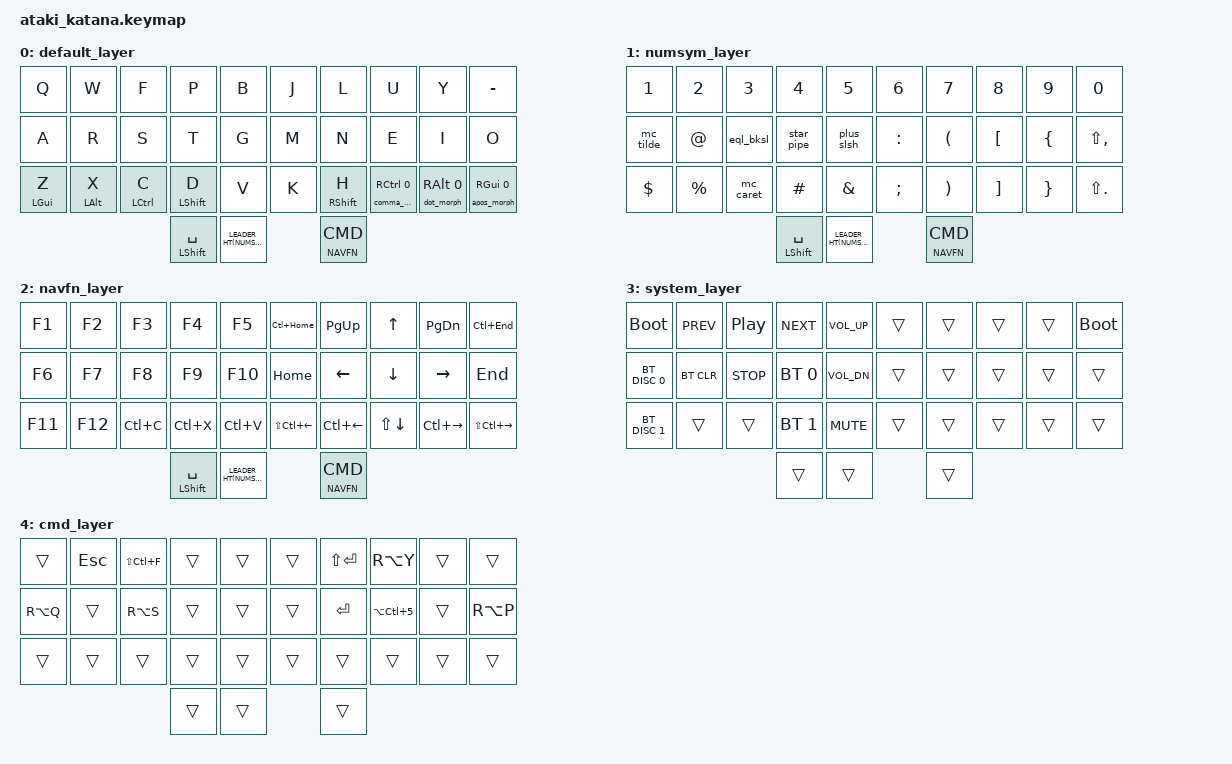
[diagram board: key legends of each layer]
#include <behaviors.dtsi>
#include <dt-bindings/zmk/keys.h>
#include <dt-bindings/zmk/bt.h>
#include <dt-bindings/zmk/pointing.h>
#include "inc/helpers.h"

// Layers
#define BASE 0
#define NUMSYM 1
#define NAVFN 2
#define SYSTEM 3
#define CMD 4
#define BASE_LAYERS BASE

#define ___ &trans

/* How quickly Combo keys must be pressed together */
#define COMBO_TIMEOUT_MS 30
/* Macro timers; can be increased for systems that don't like 0ms Macros */
#define FAST_MACRO_TAP_MS 0
#define FAST_MACRO_WAIT_MS 0

#define LEADER_HT(hold_layer) &leader_ht hold_layer 0

/* Custom base layer punctuation */
SHIFT_MORPH(comma_qust, &kp COMMA, &kp QMARK)
SHIFT_MORPH(dot_exc, &kp DOT, &kp EXCL)
SHIFT_MORPH(eql_bksl, &kp EQUAL, &kp BSLH)
SHIFT_MORPH(star_pipe, &kp STAR, &kp PIPE)
SHIFT_MORPH(plus_slsh, &kp PLUS, &kp FSLH)

MY_HOLD_TAP(dot_morph, &dot_exc, &kp)
MY_HOLD_TAP(comma_morph, &comma_qust, &kp)
MY_HOLD_TAP(apos_morph, &mc_apos, &kp)

#include "inc/urob_leader.h"

/ {
    behaviors {
       ht: hold_tap {
            compatible = "zmk,behavior-hold-tap";
            #binding-cells = <2>;
            flavor = "balanced";
            tapping-term-ms = <300>;
            require-prior-idle-ms = <100>;
            bindings = <&kp>, <&kp>;
        };

        /* Let Caps Word continue when typing Underscore */
        caps_word {
            continue-list = <UNDERSCORE MINUS BACKSPACE DELETE>;
        };

        hm: hold_mod {
            compatible = "zmk,behavior-hold-tap";
            #binding-cells = <2>;
            flavor = "balanced";
            tapping-term-ms = <300>;
            bindings = <&mo>, <&sl>;
        };
        
        leader_ht: leader_ht {
            compatible = "zmk,behavior-hold-tap";
            #binding-cells = <2>;
            flavor = "balanced";
            tapping-term-ms = <300>;
            bindings = <&mo>, <&leader>;       // Template, wird vom Makro ersetzt
        };
        
        encoder_scroll: encoder_scroll {
            compatible = "zmk,behavior-sensor-rotate";
            #sensor-binding-cells = <0>;
            bindings = <&msc SCRL_DOWN>, <&msc SCRL_UP>;
            tap-ms = <20>;
        };
    };
    
    conditional_layers {
        compatible = "zmk,conditional-layers";
        tri_layer {
            if-layers = <NUMSYM NAVFN>;
            then-layer = <SYSTEM>;
        };
    };

#include "inc/leader_macros.h" 
#include "inc/combos.h" 
    
 // cheat-sheet for indexes
 // ┌────┬──┬──┬──┬──┬──┬──┬──┬──┬────┐
 // │0   │1 │2 │3 │4 │5 │6 │7 │8 │9   │
 // ├───┬┴─┬┴─┬┴─┬┴─┬┴┬─┴┬─┴┬─┴┬─┴┬───┤
 // │10 │11│12│13│14│ │15│16│17│18│19 │
 // ├──┬┴─┬┴─┬┴─┬┴─┬┘ └┬─┴┬─┴┬─┴┬─┴┬──┤
 // │20│21│22│23│24│enc│25│26│27│28│29│
 // └──┴──┴─┬┴──┴──┼───┼──┴──┴┬─┴──┴──┘
 //         │30    │31 │32    │
 //         └──────┴───┴──────┘
/*
 * combos (see inc/combos.h for implementation)
 * ┌──────────┬─────┬─────┬─────┬─────┬─────┬─────┬─────┬─────┬─────────┐
 * │          │ +=Del=+=SftTab+ │+===Caps==+│     │ +=Del=+   │         │
 * │          │     │     │     │     │     │     │     │     │         │
 * ├─────────┬┴────┬┴────┬┴────┬┴────┬┴┬────┴┬────┴┬────┴┬────┴┬────────┤
 * │         │ +=BkSp=+=Tab=+  │     │ │     │     │  +=BkSp=+ │        │
 * │         │     │     │     │     │ │     │     │     │     │        │
 * ├────────┬┴────┬┴────┬┴────┬┴────┬┘ └┬────┴┬────┴┬────┴┬────┴┬───────┤
 * │   +=CtrlX+=CtrlC+CtrlV=+ │     │enc│     │     │     │+=DelWord=+  │
 * │        │     │     │     │     │   │     │     │     │     │       │
 * └────────┴─────┴────┬┴─────┴────┬┴───┴┬────┴─────┴┬────┴─────┴───────┘
 *                     │           │  +=system==+    │
 *                     │           │     │           │
 *                     └───────────┴─────┴───────────┘
 */
    keymap {
        compatible = "zmk,keymap";
/*
 * ┌──────────┬─────┬─────┬─────┬─────┬─────┬─────┬─────┬─────┬─────────┐
 * │q         │w    │f    │p    │b    │j    │l    │u    │y    │- _      │
 * │          │     │     │     │     │     │     │     │     │         │
 * ├─────────┬┴────┬┴────┬┴────┬┴────┬┴┬────┴┬────┴┬────┴┬────┴┬────────┤
 * │a        │r    │s    │t    │g    │ │m    │n    │e    │i    │o       │
 * │         │     │     │     │     │ │     │     │     │     │        │
 * ├────────┬┴────┬┴────┬┴────┬┴────┬┘ └┬────┴┬────┴┬────┴┬────┴┬───────┤
 * │z       │x    │c    │d    │v    │   │k    │h    │, ?  │. !  │' "    │
 * │lgui    │lalt │lctl │lshft│     │enc│     │rshft│rctl │ralt │rgui   │
 * └────────┴─────┴────┬┴─────┴────┬┴───┴┬────┴─────┴┬────┴─────┴───────┘
 *                     │space      │lead │cmd        │
 *                     │shift      │numsy│navfn      │
 *                     └───────────┴─────┴───────────┘
 */
        default_layer {
            bindings = <
            &kp Q      &kp W      &kp F      &kp P       &kp B           &kp J &kp L       &kp U               &kp Y             &kp MINUS
            &kp A      &kp R      &kp S      &kp T       &kp G           &kp M &kp N       &kp E               &kp I             &kp O
            &ht LGUI Z &ht LALT X &ht LCTL C &ht LSHFT D &kp V           &kp K &ht RSHFT H &comma_morph RCTL 0 &dot_morph RALT 0 &apos_morph RGUI 0
                                           &mt LSHFT SPACE LEADER_HT(NUMSYM) &hm NAVFN CMD
            >;
            sensor-bindings = <&encoder_scroll>;
        };

/*
 * ┌──────────┬─────┬─────┬─────┬─────┬─────┬─────┬─────┬─────┬─────────┐
 * │1         │2    │3    │4    │5    │6    │7    │8    │9    │0        │
 * │          │     │     │     │     │     │     │     │     │         │
 * ├─────────┬┴────┬┴────┬┴────┬┴────┬┴┬────┴┬────┴┬────┴┬────┴┬────────┤
 * │~        │@    │= \  │* |  │+ /  │ │:    │(    │[    │{    │<       │
 * │         │     │     │     │     │ │     │     │     │     │        │
 * ├────────┬┴────┬┴────┬┴────┬┴────┬┘ └┬────┴┬────┴┬────┴┬────┴┬───────┤
 * │$       │%    │^    │#    │&    │   │;    │)    │] ,  │} .  │>      │
 * │        │     │     │     │     │enc│     │     │     │     │       │
 * └────────┴─────┴────┬┴─────┴────┬┴───┴┬────┴─────┴┬────┴─────┴───────┘
 *                     │space      │lead │cmd        │
 *                     │shift      │numsy│navfn      │
 *                     └───────────┴─────┴───────────┘
 */
        numsym_layer {
            bindings = <
            &kp N1     &kp N2    &kp N3    &kp N4     &kp N5          &kp N6    &kp N7   &kp N8   &kp N9   &kp N0
            &mc_tilde  &kp AT    &eql_bksl &star_pipe &plus_slsh      &kp COLON &kp LPAR &kp LBKT &kp LBRC &kp LS(COMMA)      
            &kp DOLLAR &kp PRCNT &mc_caret &kp HASH   &kp AMPS        &kp SEMI  &kp RPAR &kp RBKT &kp RBRC &kp LS(DOT)      
                                           &mt LSHFT SPACE LEADER_HT(NUMSYM) &hm NAVFN CMD  
            >;
            sensor-bindings = <&encoder_scroll>;
        };

/*
 * ┌──────────┬─────┬─────┬─────┬─────┬─────┬─────┬─────┬─────┬─────────┐
 * │F1        │F2   │F3   │F4   │F5   │Top  │PgUp │↑    │PgDwn│Bottm    │
 * │          │     │     │     │     │     │     │     │     │         │
 * ├─────────┬┴────┬┴────┬┴────┬┴────┬┴┬────┴┬────┴┬────┴┬────┴┬────────┤
 * │F6       │F7   │F8   │F9   │F10  │ │Home │←    │↓    │→    │End     │
 * │         │     │     │     │     │ │     │     │     │     │        │
 * ├────────┬┴────┬┴────┬┴────┬┴────┬┘ └┬────┴┬────┴┬────┴┬────┴┬───────┤
 * │F11     │F12  │CtrlC│CtrlX│CtrlV│   │SelWL│WrdLf│SelLn│WrdRg│SelWR  │
 * │        │     │     │     │     │enc│     │     │     │     │       │
 * └────────┴─────┴────┬┴─────┴────┬┴───┴┬────┴─────┴┬────┴─────┴───────┘
 *                     │space      │lead │cmd        │
 *                     │shift      │numsy│navfn      │
 *                     └───────────┴─────┴───────────┘
 */
        navfn_layer {
            bindings = <
            &kp F1  &kp F2  &kp F3    &kp F4    &kp F5          &kp LC(HOME)     &kp PG_UP    &kp UP       &kp PG_DN     &kp LC(END)
            &kp F6  &kp F7  &kp F8    &kp F9    &kp F10         &kp HOME         &kp LEFT     &kp DOWN     &kp RIGHT     &kp END        
            &kp F11 &kp F12 &kp LC(C) &kp LC(X) &kp LC(V)       &kp LS(LC(LEFT)) &kp LC(LEFT) &kp LS(DOWN) &kp LC(RIGHT) &kp LS(LC(RIGHT))   
                                     &mt LSHFT SPACE LEADER_HT(NUMSYM) &hm NAVFN CMD
            >;
            sensor-bindings = <&encoder_scroll>;
        };

/*
 * ┌──────────┬─────┬─────┬─────┬─────┬─────┬─────┬─────┬─────┬─────────┐
 * │Boot      │track│play │track│vol  │     │     │     │     │         │
 * │          │prev │pause│next │up   │     │     │     │     │         │
 * ├─────────┬┴────┬┴────┬┴────┬┴────┬┴┬────┴┬────┴┬────┴┬────┴┬────────┤
 * │RGB      │RGB  │stop │RGB  │vol  │ │     │     │     │     │        │
 * │Sat+     │Lum+ │     │Hue+ │down │ │     │     │     │     │        │
 * ├────────┬┴────┬┴────┬┴────┬┴────┬┘ └┬────┴┬────┴┬────┴┬────┴┬───────┤
 * │RGB     │RGB  │RGB  │RGB  │vol  │   │     │     │     │     │       │
 * │Sat-    │Lum- │Mode │Hue- │mute │enc│     │     │     │     │       │
 * └────────┴─────┴────┬┴─────┴────┬┴───┴┬────┴─────┴┬────┴─────┴───────┘
 *                     │           │     │           │
 *                     │           │     │           │
 *                     └───────────┴─────┴───────────┘
 */
        system_layer {
            bindings = <
            &bootloader   &kp C_PREV &kp C_PP   &kp C_NEXT   &kp C_VOL_UP ___ ___ ___ ___ &bootloader
            &bt BT_DISC 0 &bt BT_CLR &kp C_STOP &bt BT_SEL 0 &kp C_VOL_DN ___ ___ ___ ___ ___       
            &bt BT_DISC 1 ___        ___        &bt BT_SEL 1 &kp C_MUTE   ___ ___ ___ ___ ___       
            ___           ___        ___
            >;
            sensor-bindings = <&encoder_scroll>;
        };

/*
 * ┌──────────┬─────┬─────┬─────┬─────┬─────┬─────┬─────┬─────┬─────────┐
 * │          │Esc  │Ctrl │     │     │     │Sft+ │ü    │     │         │
 * │          │     │Sft F│     │     │     │Retrn│     │     │         │
 * ├─────────┬┴────┬┴────┬┴────┬┴────┬┴┬────┴┬────┴┬────┴┬────┴┬────────┤
 * │ä        │     │ß    │     │     │ │     │Retrn│€    │     │ö       │
 * │         │     │     │     │     │ │     │     │     │     │        │
 * ├────────┬┴────┬┴────┬┴────┬┴────┬┘ └┬────┴┬────┴┬────┴┬────┴┬───────┤
 * │        │     │     │     │     │   │     │     │     │     │       │
 * │        │     │     │     │     │enc│     │     │     │     │       │
 * └────────┴─────┴────┬┴─────┴────┬┴───┴┬────┴─────┴┬────┴─────┴───────┘
 *                     │           │     │           │
 *                     │           │     │           │
 *                     └───────────┴─────┴───────────┘
 */
        cmd_layer {
            bindings = <
            ___       &kp ESC   &kp LS(LC(F)) ___ ___ ___ &kp LS(RET) &kp RA(Y)      ___ ___
            &kp RA(Q) ___       &kp RA(S)     ___ ___ ___ &kp RET     &kp LA(LC(N5)) ___ &kp RA(P)
            ___       ___       ___           ___ ___ ___ ___         ___            ___ ___
            ___       ___       ___
            >;
            sensor-bindings = <&encoder_scroll>;
        };
    };
/*
 * leader one-key (see inc/leader_macros.h for implementation)
 * ┌──────────┬─────┬─────┬─────┬─────┬─────┬─────┬─────┬─────┬─────────┐
 * │Lock      │     │Doubl│Comnt│Multi│MltCm│Multi│Dupli│     │         │
 * │          │     │Shift│     │Comnt│InteJ│Code │Line │     │         │
 * ├─────────┬┴────┬┴────┬┴────┬┴────┬┴┬────┴┬────┴┬────┴┬────┴┬────────┤
 * │->       │WinR │PrtSc│Mute/│     │ │- [ ]│()   │[]   │{}   │´´      │
 * │         │     │     │Unmte│     │ │     │     │     │     │        │
 * ├────────┬┴────┬┴────┬┴────┬┴────┬┘ └┬────┴┬────┴┬────┴┬────┴┬───────┤
 * │CtrlZ   │CtrlY│CtrlC│CtrlX│CtrlV│   │Alt  │Shift│     │     │""     │
 * │        │     │     │     │     │enc│CtrlV│CtrlV│     │     │       │
 * └────────┴─────┴────┬┴─────┴────┬┴───┴┬────┴─────┴┬────┴─────┴───────┘
 *                     │WinLf      │/lead│WinRg      │
 *                     │           │     │           │
 *                     └───────────┴─────┴───────────┘
 */
};
